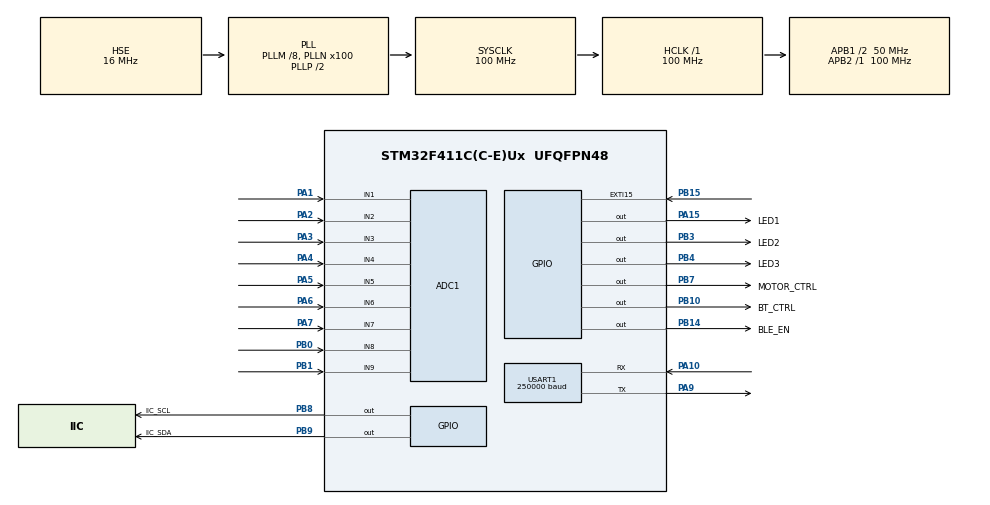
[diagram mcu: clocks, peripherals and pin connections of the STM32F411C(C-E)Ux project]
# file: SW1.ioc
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ADC1.Channel-1\#ChannelRegularConversion=ADC_CHANNEL_1
ADC1.Channel-2\#ChannelRegularConversion=ADC_CHANNEL_2
ADC1.Channel-3\#ChannelRegularConversion=ADC_CHANNEL_3
ADC1.Channel-4\#ChannelRegularConversion=ADC_CHANNEL_4
ADC1.Channel-5\#ChannelRegularConversion=ADC_CHANNEL_5
ADC1.Channel-6\#ChannelRegularConversion=ADC_CHANNEL_6
ADC1.Channel-7\#ChannelRegularConversion=ADC_CHANNEL_7
ADC1.Channel-8\#ChannelRegularConversion=ADC_CHANNEL_8
ADC1.Channel-9\#ChannelRegularConversion=ADC_CHANNEL_9
ADC1.ClockPrescaler=ADC_CLOCK_SYNC_PCLK_DIV8
ADC1.ContinuousConvMode=ENABLE
ADC1.DMAContinuousRequests=ENABLE
ADC1.InjNumberOfConversion=0
ADC1.NbrOfConversion=9
ADC1.NbrOfConversionFlag=1
ADC1.Rank-1\#ChannelRegularConversion=1
ADC1.Rank-2\#ChannelRegularConversion=2
ADC1.Rank-3\#ChannelRegularConversion=3
ADC1.Rank-4\#ChannelRegularConversion=4
ADC1.Rank-5\#ChannelRegularConversion=5
ADC1.Rank-6\#ChannelRegularConversion=6
ADC1.Rank-7\#ChannelRegularConversion=7
ADC1.Rank-8\#ChannelRegularConversion=8
ADC1.Rank-9\#ChannelRegularConversion=9
ADC1.SamplingTime-1\#ChannelRegularConversion=ADC_SAMPLETIME_144CYCLES
ADC1.SamplingTime-2\#ChannelRegularConversion=ADC_SAMPLETIME_144CYCLES
ADC1.SamplingTime-3\#ChannelRegularConversion=ADC_SAMPLETIME_144CYCLES
ADC1.SamplingTime-4\#ChannelRegularConversion=ADC_SAMPLETIME_144CYCLES
ADC1.SamplingTime-5\#ChannelRegularConversion=ADC_SAMPLETIME_144CYCLES
ADC1.SamplingTime-6\#ChannelRegularConversion=ADC_SAMPLETIME_144CYCLES
ADC1.SamplingTime-7\#ChannelRegularConversion=ADC_SAMPLETIME_144CYCLES
ADC1.SamplingTime-8\#ChannelRegularConversion=ADC_SAMPLETIME_144CYCLES
ADC1.SamplingTime-9\#ChannelRegularConversion=ADC_SAMPLETIME_144CYCLES
ADC1.ScanConvMode=ENABLE
ADC1.master=1
Dma.ADC1.0.Direction=DMA_PERIPH_TO_MEMORY
Dma.ADC1.0.FIFOMode=DMA_FIFOMODE_DISABLE
Dma.ADC1.0.Instance=DMA2_Stream0
Dma.ADC1.0.MemDataAlignment=DMA_MDATAALIGN_WORD
Dma.ADC1.0.MemInc=DMA_MINC_ENABLE
Dma.ADC1.0.Mode=DMA_CIRCULAR
Dma.ADC1.0.PeriphDataAlignment=DMA_PDATAALIGN_WORD
Dma.ADC1.0.PeriphInc=DMA_PINC_DISABLE
Dma.ADC1.0.Priority=DMA_PRIORITY_HIGH
Dma.Request0=ADC1
Dma.Request1=USART1_TX
Dma.USART1_TX.1.Direction=DMA_MEMORY_TO_PERIPH
Dma.USART1_TX.1.FIFOMode=DMA_FIFOMODE_DISABLE
Dma.USART1_TX.1.Instance=DMA2_Stream7
Dma.USART1_TX.1.MemDataAlignment=DMA_MDATAALIGN_BYTE
Dma.USART1_TX.1.MemInc=DMA_MINC_ENABLE
Dma.USART1_TX.1.Mode=DMA_NORMAL
Dma.USART1_TX.1.PeriphDataAlignment=DMA_PDATAALIGN_BYTE
Dma.USART1_TX.1.PeriphInc=DMA_PINC_DISABLE
Dma.USART1_TX.1.Priority=DMA_PRIORITY_MEDIUM
Mcu.Family=STM32F4
Mcu.Name=STM32F411C(C-E)Ux
Mcu.Package=UFQFPN48
NVIC.DMA2_Stream0_IRQn=true\:5\:0\:true\:false\:true\:false\:true
NVIC.DMA2_Stream7_IRQn=true\:4\:0\:true\:false\:true\:false\:true
NVIC.EXTI15_10_IRQn=true\:1\:0\:true\:false\:true\:true\:true
NVIC.PriorityGroup=NVIC_PRIORITYGROUP_4
NVIC.TIM1_TRG_COM_TIM11_IRQn=true\:6\:0\:true\:false\:true\:true\:true
NVIC.TIM1_UP_TIM10_IRQn=true\:3\:0\:true\:false\:true\:true\:true
NVIC.USART1_IRQn=true\:2\:0\:true\:false\:true\:true\:true
PA0-WKUP.Mode=SYS_WakeUp0
PA0-WKUP.Signal=SYS_WKUP
PA1.Signal=ADCx_IN1
PA10.Mode=Asynchronous
PA10.Signal=USART1_RX
PA13.Mode=Serial_Wire
PA13.Signal=SYS_JTMS-SWDIO
PA14.Mode=Serial_Wire
PA14.Signal=SYS_JTCK-SWCLK
PA15.GPIO_Label=LED1
PA15.PinState=GPIO_PIN_SET
PA15.Signal=GPIO_Output
PA2.Signal=ADCx_IN2
PA3.Signal=ADCx_IN3
PA4.Signal=ADCx_IN4
PA5.Signal=ADCx_IN5
PA6.Signal=ADCx_IN6
PA7.Signal=ADCx_IN7
PA9.Mode=Asynchronous
PA9.Signal=USART1_TX
PB0.Signal=ADCx_IN8
PB1.Signal=ADCx_IN9
PB10.GPIO_Label=BT_CTRL
PB10.PinState=GPIO_PIN_RESET
PB10.Signal=GPIO_Output
PB14.GPIO_Label=BLE_EN
PB14.PinState=GPIO_PIN_SET
PB14.Signal=GPIO_Output
PB15.GPIO_ModeDefaultEXTI=GPIO_MODE_IT_RISING
PB15.GPIO_PuPd=GPIO_PULLDOWN
PB15.Signal=GPXTI15
PB3.GPIO_Label=LED2
PB3.PinState=GPIO_PIN_SET
PB3.Signal=GPIO_Output
PB4.GPIO_Label=LED3
PB4.PinState=GPIO_PIN_SET
PB4.Signal=GPIO_Output
PB7.GPIO_Label=MOTOR_CTRL
PB7.PinState=GPIO_PIN_SET
PB7.Signal=GPIO_Output
PB8.GPIO_Label=IIC_SCL
PB8.GPIO_ModeDefaultOutputPP=GPIO_MODE_OUTPUT_OD
PB8.GPIO_Speed=GPIO_SPEED_FREQ_HIGH
PB8.PinState=GPIO_PIN_SET
PB8.Signal=GPIO_Output
PB9.GPIO_Label=IIC_SDA
PB9.GPIO_ModeDefaultOutputPP=GPIO_MODE_OUTPUT_OD
PB9.GPIO_Speed=GPIO_SPEED_FREQ_HIGH
PB9.PinState=GPIO_PIN_SET
PB9.Signal=GPIO_Output
PH0\ -\ OSC_IN.Mode=HSE-External-Oscillator
PH0\ -\ OSC_IN.Signal=RCC_OSC_IN
PH1\ -\ OSC_OUT.Mode=HSE-External-Oscillator
PH1\ -\ OSC_OUT.Signal=RCC_OSC_OUT
ProjectManager.HeapSize=0x200
ProjectManager.StackSize=0x400
ProjectManager.TargetToolchain=MDK-ARM V5.27
RCC.48MHZClocksFreq_Value=50000000
RCC.AHBFreq_Value=100000000
RCC.APB1CLKDivider=RCC_HCLK_DIV2
RCC.APB1Freq_Value=50000000
RCC.APB1TimFreq_Value=100000000
RCC.APB2Freq_Value=100000000
RCC.APB2TimFreq_Value=100000000
RCC.CortexFreq_Value=100000000
RCC.HCLKFreq_Value=100000000
RCC.HSE_VALUE=16000000
RCC.HSI_VALUE=16000000
RCC.LSE_VALUE=32768
RCC.PLLM=8
RCC.PLLN=100
RCC.PLLSourceVirtual=RCC_PLLSOURCE_HSE
RCC.SYSCLKFreq_VALUE=100000000
RCC.SYSCLKSource=RCC_SYSCLKSOURCE_PLLCLK
RCC.VCOOutputFreq_Value=200000000
SH.ADCx_IN1.0=ADC1_IN1,IN1
SH.ADCx_IN2.0=ADC1_IN2,IN2
SH.ADCx_IN3.0=ADC1_IN3,IN3
SH.ADCx_IN4.0=ADC1_IN4,IN4
SH.ADCx_IN5.0=ADC1_IN5,IN5
SH.ADCx_IN6.0=ADC1_IN6,IN6
SH.ADCx_IN7.0=ADC1_IN7,IN7
SH.ADCx_IN8.0=ADC1_IN8,IN8
SH.ADCx_IN9.0=ADC1_IN9,IN9
TIM10.Period=1999
TIM10.Prescaler=99
TIM11.Period=49999
TIM11.Prescaler=99
USART1.BaudRate=250000
USART1.VirtualMode=VM_ASYNC
VP_TIM10_VS_ClockSourceINT.Mode=Enable_Timer
VP_TIM11_VS_ClockSourceINT.Mode=Enable_Timer
board=custom

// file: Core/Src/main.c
/* USER CODE BEGIN Header */
/**
  ******************************************************************************
  * @file           : main.c
  * @brief          : Main program body
  ******************************************************************************
  * @attention
  *
  * <h2><center>&copy; Copyright (c) 2020 STMicroelectronics.
  * All rights reserved.</center></h2>
  *
  * This software component is licensed by ST under BSD 3-Clause license,
  * the "License"; You may not use this file except in compliance with the
  * License. You may obtain a copy of the License at:
  *                        opensource.org/licenses/BSD-3-Clause
  *
  ******************************************************************************
  */
/* USER CODE END Header */
#include "main.h"
#include "adc.h"
#include "dma.h"
#include "tim.h"
#include "usart.h"
#include "gpio.h"

/* USER CODE BEGIN Includes */
#include "app_test.h"
/* USER CODE END Includes */

/* USER CODE BEGIN PV */
uint32_t AD_Value[9]={0};/* 8->EMG;1->battery*/
/* USER CODE END PV */

void SystemClock_Config(void);

int main(void)
{

  /* MCU Configuration--------------------------------------------------------*/

  /* Reset of all peripherals, Initializes the Flash interface and the Systick. */
  HAL_Init();

  /* Configure the system clock */
  SystemClock_Config();

  /* Initialize all configured peripherals */
  MX_GPIO_Init();
  MX_DMA_Init();
  MX_ADC1_Init();
  MX_TIM10_Init();
  MX_USART1_UART_Init();
  MX_TIM11_Init();
  /* USER CODE BEGIN 2 */
	//Main_Init();
	HAL_ADC_Start_DMA(&hadc1,AD_Value,9);//ADC循环模式开启
  /* USER CODE END 2 */

  /* Infinite loop */
  while (1)
  {

    /* USER CODE BEGIN 3 */
	//	Mainloop();
  }
  /* USER CODE END 3 */
}

void SystemClock_Config(void)
{
  RCC_OscInitTypeDef RCC_OscInitStruct = {0};
  RCC_ClkInitTypeDef RCC_ClkInitStruct = {0};

  /** Configure the main internal regulator output voltage
  */
  __HAL_RCC_PWR_CLK_ENABLE();
  __HAL_PWR_VOLTAGESCALING_CONFIG(PWR_REGULATOR_VOLTAGE_SCALE1);
  /** Initializes the RCC Oscillators according to the specified parameters
  * in the RCC_OscInitTypeDef structure.
  */
  RCC_OscInitStruct.OscillatorType = RCC_OSCILLATORTYPE_HSE;
  RCC_OscInitStruct.HSEState = RCC_HSE_ON;
  RCC_OscInitStruct.PLL.PLLState = RCC_PLL_ON;
  RCC_OscInitStruct.PLL.PLLSource = RCC_PLLSOURCE_HSE;
  RCC_OscInitStruct.PLL.PLLM = 8;
  RCC_OscInitStruct.PLL.PLLN = 100;
  RCC_OscInitStruct.PLL.PLLP = RCC_PLLP_DIV2;
  RCC_OscInitStruct.PLL.PLLQ = 4;
  if (HAL_RCC_OscConfig(&RCC_OscInitStruct) != HAL_OK)
  {
    Error_Handler();
  }
  /** Initializes the CPU, AHB and APB buses clocks
  */
  RCC_ClkInitStruct.ClockType = RCC_CLOCKTYPE_HCLK|RCC_CLOCKTYPE_SYSCLK
                              |RCC_CLOCKTYPE_PCLK1|RCC_CLOCKTYPE_PCLK2;
  RCC_ClkInitStruct.SYSCLKSource = RCC_SYSCLKSOURCE_PLLCLK;
  RCC_ClkInitStruct.AHBCLKDivider = RCC_SYSCLK_DIV1;
  RCC_ClkInitStruct.APB1CLKDivider = RCC_HCLK_DIV2;
  RCC_ClkInitStruct.APB2CLKDivider = RCC_HCLK_DIV1;

  if (HAL_RCC_ClockConfig(&RCC_ClkInitStruct, FLASH_LATENCY_3) != HAL_OK)
  {
    Error_Handler();
  }
}

void Error_Handler(void)
{
}

/************************ (C) COPYRIGHT STMicroelectronics *****END OF FILE****/
